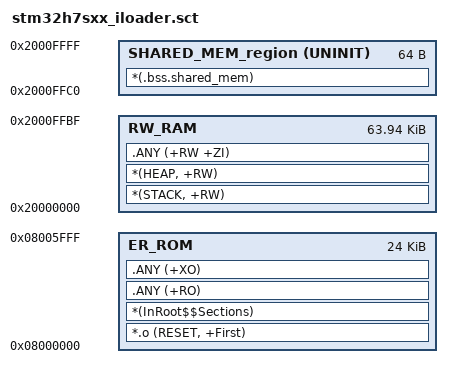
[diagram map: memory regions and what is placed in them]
#! armclang --target=arm-arm-none-eabi -march=armv7-m -E -xc

; *************************************************************
; *** Scatter-Loading Description File generated by uVision ***
; *************************************************************

#define CODE_OFFSET 0x0    /* Firmware execution area offset from STiROT_Config.xml */
#define CODE_SIZE 0x6000      /* Firmware area size from STiROT_Config.xml */

#define CODE_START (0x08000000 + CODE_OFFSET)
#define APP_CODE_SIZE CODE_SIZE

LOAD_FLASH CODE_START CODE_SIZE  {    ; load region size_region
  ER_ROM CODE_START APP_CODE_SIZE  {  ; load address = execution address
   *.o (RESET, +First)
   *(InRoot$$Sections)
   .ANY (+RO)
   .ANY (+XO)
  }

  RW_RAM 0x20000000  0xFFC0  {
   *(STACK, +RW)
   *(HEAP, +RW)
   .ANY (+RW +ZI)
  }

  SHARED_MEM_region 0x2000FFC0 UNINIT 0x40 {
    *(.bss.shared_mem)
  }


}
